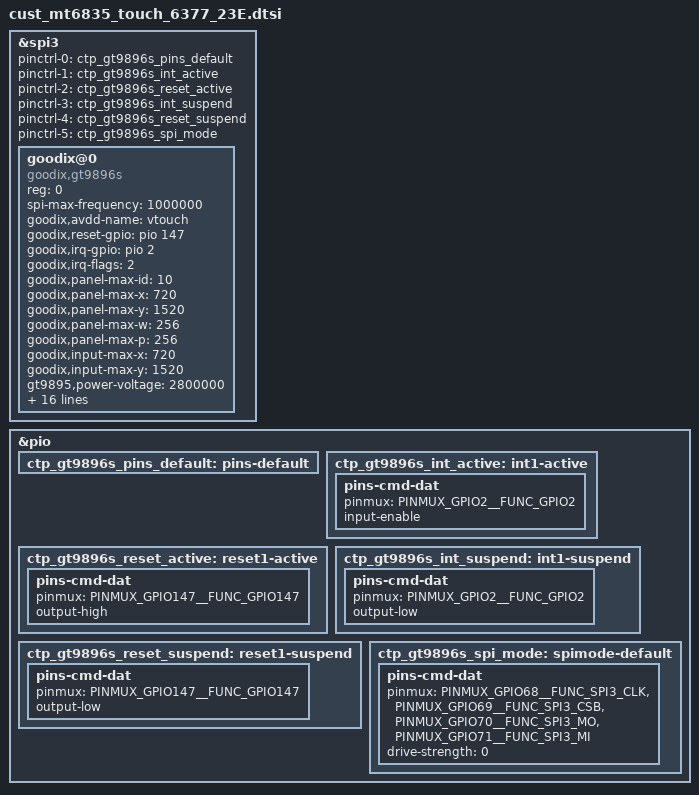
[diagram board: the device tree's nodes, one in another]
// SPDX-License-Identifier: (GPL-2.0 OR MIT)
/*
 * Copyright (C) 2020 MediaTek Inc.
 */

/* TOUCH start */

&spi3 {
	status = "okay";
	#address-cells = <1>;
	#size-cells = <0>;
	pinctrl-names = "default", "gt9896s_int_active",
		"gt9896s_reset_active", "gt9896s_int_suspend",
		"gt9896s_reset_suspend", "gt9896s_spi_mode";
	pinctrl-0 = <&ctp_gt9896s_pins_default>;
	pinctrl-1 = <&ctp_gt9896s_int_active>;
	pinctrl-2 = <&ctp_gt9896s_reset_active>;
	pinctrl-3 = <&ctp_gt9896s_int_suspend>;
	pinctrl-4 = <&ctp_gt9896s_reset_suspend>;
	pinctrl-5 = <&ctp_gt9896s_spi_mode>;

	goodix@0 {
		compatible = "goodix,gt9896s", "goodix,nottingham";
		reg = <0>; //Same as CS ID
		spi-max-frequency = <1000000>;

		goodix,avdd-name = "vtouch";
		/* vtouch-supply = <&mt6377_vtp>; */
		goodix,reset-gpio = <&pio 147 0x0>;
		goodix,irq-gpio = <&pio 2 0x0>;
		goodix,irq-flags = <2>; /* 1:rising, 2:falling;*/
		goodix,panel-max-id = <10>;
		goodix,panel-max-x = <720>;
		goodix,panel-max-y = <1520>;
		goodix,panel-max-w = <256>;
		goodix,panel-max-p = <256>;
		goodix,input-max-x = <720>;
		goodix,input-max-y = <1520>;
		gt9895,power-voltage = <2800000>;
		goodix,panel-key-map = <158 172 217>; /*BACK,HOMEPAGE,SEARCH*/
		goodix,power-on-delay-us = <10000>; /*10ms*/
		goodix,power-off-delay-us = <5000>;
		gt9895,firmware-name = "gt9895_firmware_6835v01.bin";
		gt9895,config-name = "gt9895_cfg_6835v01.bin";
		goodix,firmware-version = "6983v01";
		goodix,config-version = "6983v01";
		/*goodix,swap-axis;*/
		/*gt9895,x2x;*/
		/*gt9895,y2y;*/
		goodix,x2x;
		goodix,y2y;
		goodix,pen-enable;
		tpd-filter-enable = <0>;
		tpd-filter-pixel-density = <161>;
		tpd-filter-custom-prameters = <0 0 0 0 0 0 0 0 0 0 0 0>;
		tpd-filter-custom-speed = <0 0 0>;
	};

};

&pio {
	ctp_gt9896s_pins_default: pins-default {
	};
	ctp_gt9896s_int_active: int1-active {
		pins-cmd-dat {
			pinmux = <PINMUX_GPIO2__FUNC_GPIO2>;
			input-enable;
		};
	};
	ctp_gt9896s_reset_active: reset1-active {
		pins-cmd-dat {
			pinmux = <PINMUX_GPIO147__FUNC_GPIO147>;
			output-high;
		};
	};
	ctp_gt9896s_int_suspend: int1-suspend {
		pins-cmd-dat {
			pinmux = <PINMUX_GPIO2__FUNC_GPIO2>;
			output-low;
		};
	};
	ctp_gt9896s_reset_suspend: reset1-suspend {
		pins-cmd-dat {
			pinmux = <PINMUX_GPIO147__FUNC_GPIO147>;
			output-low;
		};
	};
	ctp_gt9896s_spi_mode: spimode-default {
		pins-cmd-dat {
			pinmux = <PINMUX_GPIO68__FUNC_SPI3_CLK>,
				<PINMUX_GPIO69__FUNC_SPI3_CSB>,
				<PINMUX_GPIO70__FUNC_SPI3_MO>,
				<PINMUX_GPIO71__FUNC_SPI3_MI>;
			drive-strength = <0>;
		};
	};
};
/* TOUCH end */

